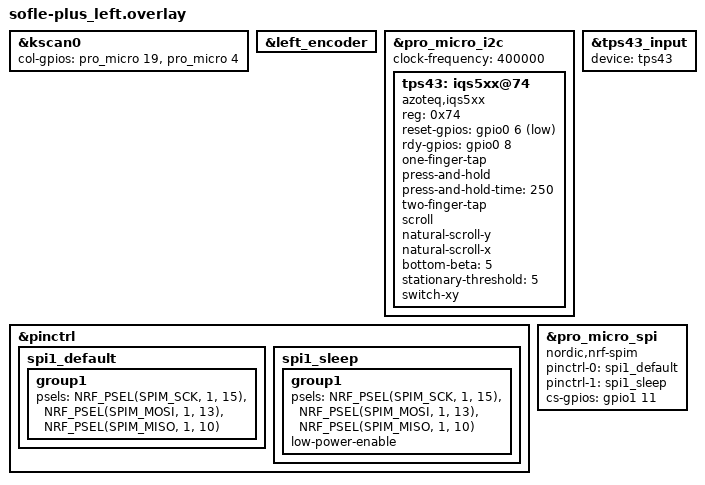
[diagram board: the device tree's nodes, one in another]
/*
 * Copyright (c) 2020 Ryan Cross
 *
 * SPDX-License-Identifier: MIT
 */

#include "sofle-plus.dtsi"

&kscan0 {
    col-gpios
        = <&pro_micro 19 GPIO_ACTIVE_HIGH>
        , <&pro_micro 4 GPIO_ACTIVE_HIGH>
        ;
};

&left_encoder {
    status = "okay";
};

&pro_micro_i2c {
	status = "okay";
	clock-frequency = <400000>; 
	tps43: iqs5xx@74 {
		status = "okay";
		compatible = "azoteq,iqs5xx";
		reg = <0x74>;

		reset-gpios = <&gpio0 6 GPIO_ACTIVE_LOW>;
		rdy-gpios = <&gpio0 8 GPIO_ACTIVE_HIGH>;

		/*
		* Potentially non-exhaustive list of configuration options.
		* See: dts/bindings/input/azoteq,iqs5xx-common.yaml for a full list.
		*/
		one-finger-tap;
		press-and-hold;
		press-and-hold-time = <250>;
		two-finger-tap;

		scroll;
		natural-scroll-y;
		natural-scroll-x;

		// If the beta is small, the filtering is stronger, and if the beta is larger, the filtering is weaker.
		bottom-beta = <5>;
		stationary-threshold = <5>;

		switch-xy;
	};
};

&pinctrl {
    spi1_default: spi1_default {
        group1 {
            psels = <NRF_PSEL(SPIM_SCK, 1, 15)>,
                <NRF_PSEL(SPIM_MOSI, 1, 13)>,
                <NRF_PSEL(SPIM_MISO, 1, 10)>;
        };
    };

    spi1_sleep: spi1_sleep {
        group1 {
            psels = <NRF_PSEL(SPIM_SCK, 1, 15)>,
                <NRF_PSEL(SPIM_MOSI, 1, 13)>,
                <NRF_PSEL(SPIM_MISO, 1, 10)>;
            low-power-enable;
        };
    };
};

&tps43_input {
		status = "okay";
	 device= <&tps43>;
};

nice_view_spi: &pro_micro_spi {
    compatible = "nordic,nrf-spim";
    pinctrl-0 = <&spi1_default>;
    pinctrl-1 = <&spi1_sleep>;
    pinctrl-names = "default", "sleep";
    cs-gpios = <&gpio1 11 GPIO_ACTIVE_HIGH>;
};
lpm_view_spi: &pro_micro_spi {
    compatible = "nordic,nrf-spim";
    pinctrl-0 = <&spi1_default>;
    pinctrl-1 = <&spi1_sleep>;
    pinctrl-names = "default", "sleep";
    cs-gpios = <&gpio1 11 (GPIO_ACTIVE_HIGH | GPIO_PULL_DOWN) >;
};
